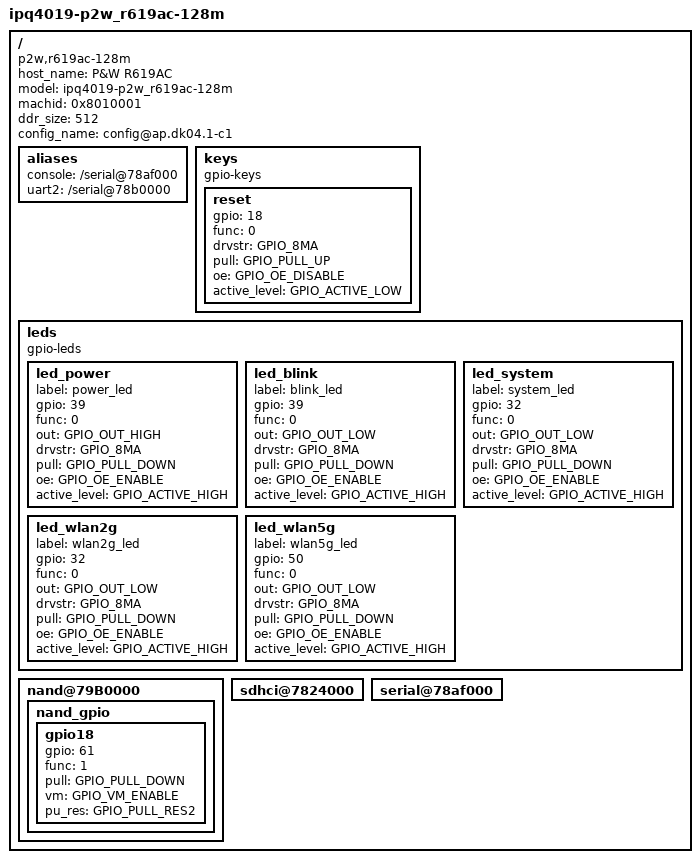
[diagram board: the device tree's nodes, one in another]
/*
 * Copyright (c) 2016, The Linux Foundation. All rights reserved.
 * Copyright (c) 2026, chenxin527. All rights reserved.
 *
 * This program is free software; you can redistribute it and/or modify
 * it under the terms of the GNU General Public License version 2 and
 * only version 2 as published by the Free Software Foundation.
 *
 * This program is distributed in the hope that it will be useful,
 * but WITHOUT ANY WARRANTY; without even the implied warranty of
 * MERCHANTABILITY or FITNESS FOR A PARTICULAR PURPOSE.  See the
 * GNU General Public License for more details.
 */

/dts-v1/;
#include "ipq40xx-dk04.dtsi"
#include "nand_gpio.dtsi"

/ {
	host_name = "P&W R619AC";
	model = "ipq4019-p2w_r619ac-128m";
	compatible = "p2w,r619ac-128m", "p2w,r619ac", "qca,ipq40xx", "qca,ipq40xx-dk04";
	machid = <0x8010001>;
	ddr_size = <512>;
	config_name = "config@ap.dk04.1-c1";

	aliases {
		console = "/serial@78af000";
		uart2 = "/serial@78b0000";
	};

	keys {
		compatible = "gpio-keys";

		reset {
			gpio = <18>;
			func = <0>;
			drvstr = <GPIO_8MA>;
			pull = <GPIO_PULL_UP>;
			oe = <GPIO_OE_DISABLE>;
			active_level = <GPIO_ACTIVE_LOW>;
		};
	};

	leds {
		compatible = "gpio-leds";

		led_power {
			label = "power_led";
			gpio = <39>;
			func = <0>;
			out = <GPIO_OUT_HIGH>;
			drvstr = <GPIO_8MA>;
			pull = <GPIO_PULL_DOWN>;
			oe = <GPIO_OE_ENABLE>;
			active_level = <GPIO_ACTIVE_HIGH>;
		};

		led_blink {
			label = "blink_led";
			gpio = <39>;
			func = <0>;
			out = <GPIO_OUT_LOW>;
			drvstr = <GPIO_8MA>;
			pull = <GPIO_PULL_DOWN>;
			oe = <GPIO_OE_ENABLE>;
			active_level = <GPIO_ACTIVE_HIGH>;
		};

		led_system {
			label = "system_led";
			gpio = <32>;
			func = <0>;
			out = <GPIO_OUT_LOW>;
			drvstr = <GPIO_8MA>;
			pull = <GPIO_PULL_DOWN>;
			oe = <GPIO_OE_ENABLE>;
			active_level = <GPIO_ACTIVE_HIGH>;
		};

		led_wlan2g {
			label = "wlan2g_led";
			gpio = <32>;
			func = <0>;
			out = <GPIO_OUT_LOW>;
			drvstr = <GPIO_8MA>;
			pull = <GPIO_PULL_DOWN>;
			oe = <GPIO_OE_ENABLE>;
			active_level = <GPIO_ACTIVE_HIGH>;
		};

		led_wlan5g {
			label = "wlan5g_led";
			gpio = <50>;
			func = <0>;
			out = <GPIO_OUT_LOW>;
			drvstr = <GPIO_8MA>;
			pull = <GPIO_PULL_DOWN>;
			oe = <GPIO_OE_ENABLE>;
			active_level = <GPIO_ACTIVE_HIGH>;
		};
	};

	nand@79B0000 {
		status = "ok";
		nand_gpio {
			gpio18 {
				gpio = <61>;
				func = <1>;
				pull = <GPIO_PULL_DOWN>;
				vm = <GPIO_VM_ENABLE>;
				pu_res = <GPIO_PULL_RES2>;
			};
		};
	};

	sdhci@7824000 {
		status = "okay";
	};

	serial@78af000 {
		status = "ok";
	};
};
